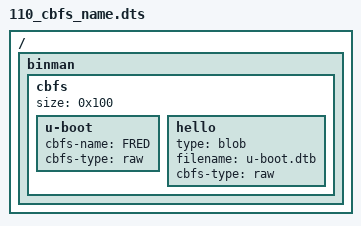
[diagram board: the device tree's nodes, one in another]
// SPDX-License-Identifier: GPL-2.0+

/dts-v1/;

/ {
	#address-cells = <1>;
	#size-cells = <1>;

	binman {
		cbfs {
			size = <0x100>;
			u-boot {
				cbfs-name = "FRED";
				cbfs-type = "raw";
			};

			hello {
				type = "blob";
				filename = "u-boot.dtb";
				cbfs-type = "raw";
			};
		};
	};
};
